# CKMD register map
Vendor: Texas Instruments
Registers are 32-bit, access per field, reset 0x0 unless marked. A register's access mark holds for its fields unless they carry their own. Offsets are as the file gives them; [hi:lo] are bit positions; 'fields as' and 'values as' point back to an identical list.

## CKMD (part 2 of 2) — Clock Controller
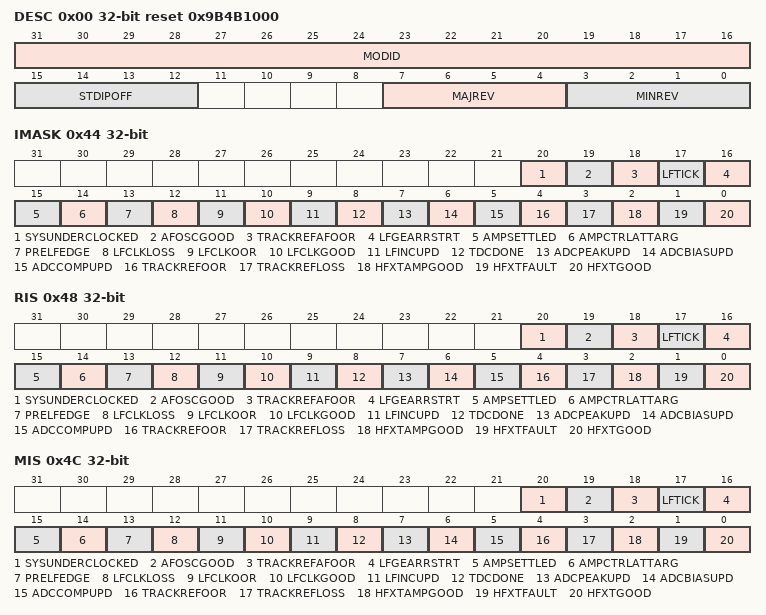
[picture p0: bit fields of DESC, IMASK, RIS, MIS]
0x00 DESC ro reset 0x9B4B1000 — IP Description
  [31:16] MODID — Module identifier
  [15:12] STDIPOFF — Standard IP MMR block offset
  [7:4] MAJREV — Major revision
  [3:0] MINREV — Minor revision
0x44 IMASK — Interrupt mask register
  [20] SYSUNDERCLOCKED rw — Indicates system frequency has been lowered. It will be set only if HFTRACKCTL.UNDERCLK is appropriately configured and HFOSC tracking loop is not running.
  [19] AFOSCGOOD rw — AFOSC good indication.
  [18] TRACKREFAFOOR rw — Out-of-range indication from the AFOSC tracking loop. Indicates that the reference clock frequency of AFOSC tracking loop is out-of-range.
  [17] LFTICK rw — 32kHz TICK to RTC and WDT. Either derived from selected LFCLK or generated from CLKULL in absence of LFCLK.
  [16] LFGEARRSTRT rw — LFINC filter gearing restart. Indicates that the LFINC filter restarted gearing. Subsequent LFINC estimates may have higher variation.
  [15] AMPSETTLED rw — HFXT Amplitude compensation - settled Indicates that the amplitude compensation FSM has reached the SETTLED or TCXOMODE state, and the controls configured in HFXTTARG or HFXTDYN are reached.
  [14] AMPCTRLATTARG rw — HFXT Amplitude compensation - controls at target Indicates that the control values configured in HFXTTARG or HFXTDYN are reached. Applies to Q1CAP, Q2CAP and IREF.
  [13] PRELFEDGE rw — Pre-LF clock edge detect. Indicates that a positive edge occured on the selected pre-LF clock CLKSEL.PRELFCLK' Can be used by software to confirm that a LF clock source is running and within the expected frequency, before selecting it as the main LF clock source.
  [12] LFCLKLOSS rw — LF clock is lost. Indicates that no LF clock edge occured for ~49us (~1.6 times nominal period). The system will automatically fall-back to generating LFTICK based on CLKULL, to avoid timing corruption. Note that this signal is NOT related to the analog LF clock-loss detector which can reset the device during STANDBY.
  [11] LFCLKOOR rw — LF clock period out-of-range. Indicates that a LF clock period was measured to be out-of-range, according to LFQUALCTL.MAXERR.
  [10] LFCLKGOOD rw — LF clock good. Indicates that the LF clock is good, according to the configuration in LFQUALCTL.
  [9] LFINCUPD rw — LFINC updated. Indicates that a new LFINC measurement value is available in CKM.LFCLKSTAT.
  [8] TDCDONE rw — TDC done event. Indicates that the TDC measurement is done.
  [7] ADCPEAKUPD rw — HFXT-ADC PEAK measurement update event. Indicates that the HFXT-ADC PEAK measurement is done.
  [6] ADCBIASUPD rw — HFXT-ADC BIAS measurement update event. Indicates that the HFXT-ADC BIAS measurement is done.
  [5] ADCCOMPUPD rw — HFXT-ADC comparison update event. Indicates that the HFXT-ADC comparison is done.
  [4] TRACKREFOOR rw — Out-of-range indication from the tracking loop. Indicates that the selected reference clock frequency of the tracking loop is out-of-range.
  [3] TRACKREFLOSS rw — Clock loss indication from the tracking loop. Indicates that the selected reference clock of the tracking loop is lost.
  [2] HFXTAMPGOOD rw — HFXT amplitude good indication.
  [1] HFXTFAULT rw — HFXT fault indication. Indicates that HFXT did not start correctly, or its frequency is too low. HFXT will not recover from this fault and has to be restarted. This is only a one-time check at HFXT startup.
  [0] HFXTGOOD rw — HFXT good indication. Indicates that HFXT started correctly. The frequency is not necessarily good enough for radio operation. This is only a one-time check at HFXT startup.
0x48 RIS ro — Raw interrupt flag register
  [20] SYSUNDERCLOCKED — Indicates system frequency has been lowered. It will be set only if HFTRACKCTL.UNDERCLK is appropriately configured and HFOSC tracking loop is not running.
  [19] AFOSCGOOD — AFOSC good indication.
  [18] TRACKREFAFOOR — Out-of-range indication from the AFOSC tracking loop. Indicates that the reference clock frequency of AFOSC tracking loop is out-of-range.
  [17] LFTICK — 32kHz TICK to RTC and WDT. Either derived from selected LFCLK or generated from CLKULL in absence of LFCLK.
  [16] LFGEARRSTRT — LFINC filter gearing restart. Indicates that the LFINC filter restarted gearing. Subsequent LFINC estimates may have higher variation.
  [15] AMPSETTLED — HFXT Amplitude compensation - settled Indicates that the amplitude compensation FSM has reached the SETTLED or TCXOMODE state, and the controls configured in HFXTTARG or HFXTDYN are reached.
  [14] AMPCTRLATTARG — HFXT Amplitude compensation - controls at target Indicates that the control values configured in HFXTTARG or HFXTDYN are reached. Applies to Q1CAP, Q2CAP and IREF.
  [13] PRELFEDGE — Pre-LF clock edge detect. Indicates that a positive edge occured on the selected pre-LF clock CLKSEL.PRELFCLK' Can be used by software to confirm that a LF clock source is running and within the expected frequency, before selecting it as the main LF clock source.
  [12] LFCLKLOSS — LF clock is lost. Indicates that no LF clock edge occured for ~49us (~1.6 times nominal period). The system will automatically fall-back to generating LFTICK based on CLKULL, to avoid timing corruption. Note that this signal is NOT related to the analog LF clock-loss detector which can reset the device during STANDBY.
  [11] LFCLKOOR — LF clock period out-of-range. Indicates that a LF clock period was measured to be out-of-range, according to LFQUALCTL.MAXERR.
  [10] LFCLKGOOD — LF clock good. Indicates that the LF clock is good, according to the configuration in LFQUALCTL.
  [9] LFINCUPD — LFINC updated. Indicates that a new LFINC measurement value is available in CKM.LFCLKSTAT.
  [8] TDCDONE — TDC done event. Indicates that the TDC measurement is done.
  [7] ADCPEAKUPD — HFXT-ADC PEAK measurement update event. Indicates that the HFXT-ADC PEAK measurement is done.
  [6] ADCBIASUPD — HFXT-ADC BIAS measurement update event. Indicates that the HFXT-ADC BIAS measurement is done.
  [5] ADCCOMPUPD — HFXT-ADC comparison update event. Indicates that the HFXT-ADC comparison is done.
  [4] TRACKREFOOR — Out-of-range indication from the tracking loop. Indicates that the selected reference clock frequency of the tracking loop is out-of-range.
  [3] TRACKREFLOSS — Clock loss indication from the tracking loop. Indicates that the selected reference clock of the tracking loop is lost.
  [2] HFXTAMPGOOD — HFXT amplitude good indication.
  [1] HFXTFAULT — HFXT fault indication. Indicates that HFXT did not start correctly, or its frequency is too low. HFXT will not recover from this fault and has to be restarted. This is only a one-time check at HFXT startup.
  [0] HFXTGOOD — HFXT good indication. Indicates that HFXT started correctly. The frequency is not necessarily good enough for radio operation. This is only a one-time check at HFXT startup.
0x4C MIS ro — Masked interrupt flag register
  fields as RIS
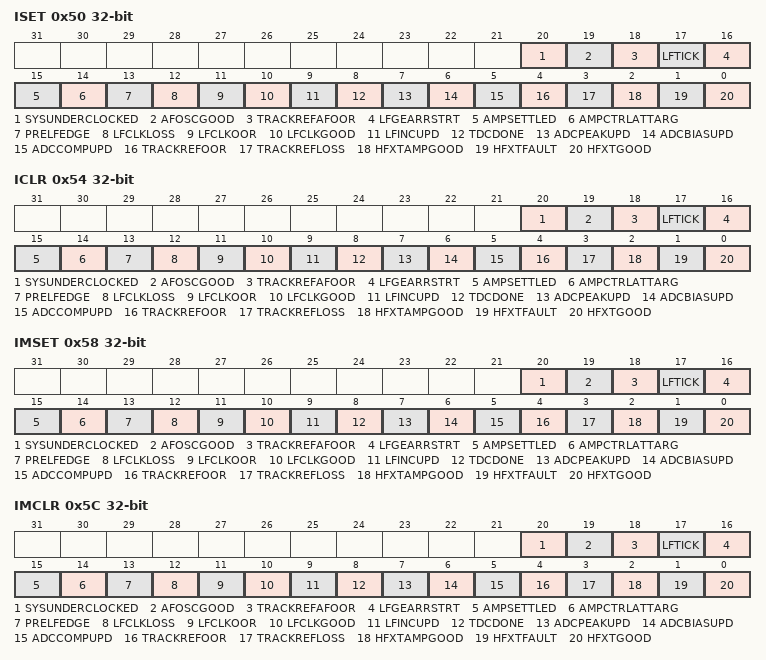
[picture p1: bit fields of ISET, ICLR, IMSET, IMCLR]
0x50 ISET — Interrupt flag set register
  [20] SYSUNDERCLOCKED wo — Indicates system frequency has been lowered. It will be set only if HFTRACKCTL.UNDERCLK is appropriately configured and HFOSC tracking loop is not running.
  [19] AFOSCGOOD wo — AFOSC good indication.
  [18] TRACKREFAFOOR wo — Out-of-range indication from the AFOSC tracking loop. Indicates that the reference clock frequency of AFOSC tracking loop is out-of-range.
  [17] LFTICK wo — 32kHz TICK to RTC and WDT. Either derived from selected LFCLK or generated from CLKULL in absence of LFCLK.
  [16] LFGEARRSTRT wo — LFINC filter gearing restart. Indicates that the LFINC filter restarted gearing. Subsequent LFINC estimates may have higher variation.
  [15] AMPSETTLED wo — HFXT Amplitude compensation - settled Indicates that the amplitude compensation FSM has reached the SETTLED or TCXOMODE state, and the controls configured in HFXTTARG or HFXTDYN are reached.
  [14] AMPCTRLATTARG wo — HFXT Amplitude compensation - controls at target Indicates that the control values configured in HFXTTARG or HFXTDYN are reached. Applies to Q1CAP, Q2CAP and IREF.
  [13] PRELFEDGE wo — Pre-LF clock edge detect. Indicates that a positive edge occured on the selected pre-LF clock CLKSEL.PRELFCLK' Can be used by software to confirm that a LF clock source is running and within the expected frequency, before selecting it as the main LF clock source.
  [12] LFCLKLOSS wo — LF clock is lost. Indicates that no LF clock edge occured for ~49us (~1.6 times nominal period). The system will automatically fall-back to generating LFTICK based on CLKULL, to avoid timing corruption. Note that this signal is NOT related to the analog LF clock-loss detector which can reset the device during STANDBY.
  [11] LFCLKOOR wo — LF clock period out-of-range. Indicates that a LF clock period was measured to be out-of-range, according to LFQUALCTL.MAXERR.
  [10] LFCLKGOOD wo — LF clock good. Indicates that the LF clock is good, according to the configuration in LFQUALCTL.
  [9] LFINCUPD wo — LFINC updated. Indicates that a new LFINC measurement value is available in CKM.LFCLKSTAT.
  [8] TDCDONE wo — TDC done event. Indicates that the TDC measurement is done.
  [7] ADCPEAKUPD wo — HFXT-ADC PEAK measurement update event. Indicates that the HFXT-ADC PEAK measurement is done.
  [6] ADCBIASUPD wo — HFXT-ADC BIAS measurement update event. Indicates that the HFXT-ADC BIAS measurement is done.
  [5] ADCCOMPUPD wo — HFXT-ADC comparison update event. Indicates that the HFXT-ADC comparison is done.
  [4] TRACKREFOOR wo — Out-of-range indication from the tracking loop. Indicates that the selected reference clock frequency of the tracking loop is out-of-range.
  [3] TRACKREFLOSS wo — Clock loss indication from the tracking loop. Indicates that the selected reference clock of the tracking loop is lost.
  [2] HFXTAMPGOOD wo — HFXT amplitude good indication.
  [1] HFXTFAULT wo — HFXT fault indication. Indicates that HFXT did not start correctly, or its frequency is too low. HFXT will not recover from this fault and has to be restarted. This is only a one-time check at HFXT startup.
  [0] HFXTGOOD wo — HFXT good indication. Indicates that HFXT started correctly. The frequency is not necessarily good enough for radio operation. This is only a one-time check at HFXT startup.
0x54 ICLR — Interrupt flag clear register
  fields as ISET
0x58 IMSET — Interrupt mask set register
  fields as ISET
0x5C IMCLR — Interrupt mask clear register
  fields as ISET
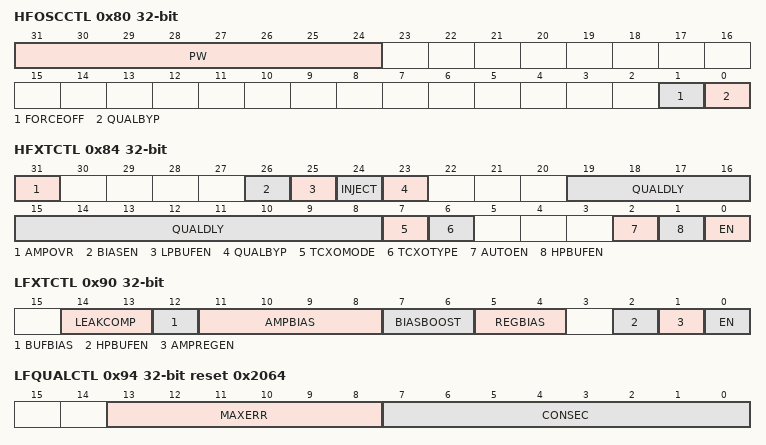
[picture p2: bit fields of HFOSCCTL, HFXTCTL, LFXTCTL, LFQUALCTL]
0x80 HFOSCCTL — High frequency oscillator control
  [31:24] PW wo — Password protection for QUALBYP and FORCEOFF. Write this field to 0xA5 to accept writes to QUALBYP and FORCEOFF.
  [1] FORCEOFF rw — Force HFOSC off. Once this MMR is set, the system will stop. The only way to start the system again is system reset. This field is locked using the global-lock within SYS0.
  [0] QUALBYP rw — Clock qualification bypass. HFOSC qualification will skip a fixed number of clock cycles to prevent glitches or frequency overshoots from reaching the system. Setting this bit will bypass the qualification. This bit can be locked in SYS0. If unlocked, it is password protected with PW.
0x84 HFXTCTL — High frequency crystal control
  [31] AMPOVR rw — Software override for the amplitude compensation FSM Directly use control values in CKM.HFXTDYN0 and CKM.HFXTDYN1. Control injection and clock buffer using INJECT and LPBUFEN.
  [26] BIASEN rw — HFXT bias enable. Controls the biasing if AMPOVR is set. Otherwise, the biasing is controlled by the amplitude compensation FSM.
  [25] LPBUFEN rw — Low power clock buffer enable. Controls the clock buffer if AMPOVR is set. Otherwise, the buffer is controlled by the amplitude compensation FSM.
  [24] INJECT rw — Control HFXT injection if AMPOVR is set.
  [23] QUALBYP rw — Bypass HFXT clock qualification. Enables HFXT propagation to the system without waiting for the qualification circuit.
  [19:8] QUALDLY rw — Skip potentially unstable clock cycles after enabling HFXT. Number of cycles skipped is 8*QUALDLY.
  [7] TCXOMODE rw — Temperature compensated crystal oscillator mode. Set this bit if a TXCO is connected.
  [6] TCXOTYPE rw — Type of temperature compensated crystal used. Only has effect if TCXOMODE is set.
    1=CMOS; 0=CLIPPEDSINE
  [2] AUTOEN rw — Automatic enable. If this bit is set, EN will automatically be set at wakeup or before (using pre-wake mechanism in RTC).
  [1] HPBUFEN rw — High performance clock buffer enable. This bit controls the clock output for the RF PLL. It is required for radio operation.
  [0] EN rw — HFXT enable. Setting this bit will enable HFXT. It will automatically be cleared upon STANDBY entry. If AUTOEN is set, this bit will be set automatically on wakeup or before (pre-wake mechanism in RTC).
0x8C LFOSCCTL — Low frequency oscillator control
  [0] EN rw — LFOSC enable
0x90 LFXTCTL — Low frequency crystal control
  [14:13] LEAKCOMP rw — Leakage compensation control
    3=OFF (No leakage compensation); 1=HALF (Half leakage compensation); 0=FULL (Full leakage compensation)
  [12] BUFBIAS rw — Control the BIAS current of the input amp in LP buffer
    1=MAX (Maximum bias current: 50nA); 0=MIN (Minimum bias current: 25nA)
  [11:8] AMPBIAS rw — Adjust current mirror ratio into oscillator core. This value is depending on crystal and is set by FW. This field uses a 2's complement encoding.
  [7:6] BIASBOOST rw — Boost oscillator amplitude This value depends on the crystal and needs to be configured by Firmware.
  [5:4] REGBIAS rw — Regulation loop bias resistor value This value depends on the crystal and needs to be configured by Firmware.
  [2] HPBUFEN rw — Control the buffer used. In normal operation, low-power buffer is used in all device modes. The high-performance buffer is only used for test purposes.
  [1] AMPREGEN rw — Amplitude regulation loop enable
  [0] EN rw — LFXT enable
0x94 LFQUALCTL reset 0x2064 — Low frequency clock qualification control
  [13:8] MAXERR rw — Maximum LFCLK period error. Value given in microseconds, 3 integer bits + 3 fractional bits.
  [7:0] CONSEC rw — Number of consecutive times the LFCLK period error has to be smaller than MAXERR to be considered "good". Setting this value to 0 will bypass clock qualification, and the "good" indicator will always be 1.
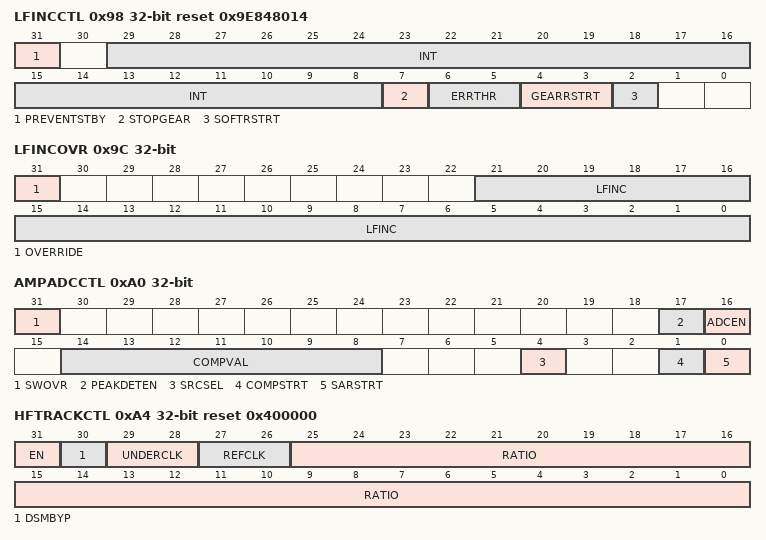
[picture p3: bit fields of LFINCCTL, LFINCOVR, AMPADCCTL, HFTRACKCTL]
0x98 LFINCCTL reset 0x9E848014 — Low frequency time increment control
  [31] PREVENTSTBY rw — Controls if the LFINC filter prevents STANBY entry until settled.
    1=ON (Enable. Prevent STANDBY entry.); 0=OFF (Disable. Do not prevent STANDBY entry.)
  [29:8] INT rw — Integral part of the LFINC filter. This value is updated by Hardware to reflect the current state of the filter. It can also be written to change the current state.
  [7] STOPGEAR rw — Controls the final gear of the LFINC filter.
    1=HIGH (Highest final gear. Best dynamic frequency tracking, but higher variation in filter value.); 0=LOW (Lowest final gear. Best settling, but less dynamic frequency tracking.)
  [6:5] ERRTHR rw — Controls the threshold for gearing restart of the LFINC filter. Only effective if GEARRSTRT is not ONETHR or TWOTHR.
    3=SMALL (Restart gearing on small error. Potentially more false restarts, faster response on small frequency shifts.); 2=MIDSMALL (Middle value towards SMALL.); 1=MIDLARGE (Middle value towards LARGE.); 0=LARGE (Restart gearing on large error. Fewer false restarts, slower response on small frequency shifts.)
  [4:3] GEARRSTRT rw — Controls gearing restart of the LFINC filter.
    2=TWOTHR (Restart gearing when the error accumulator crosses the threshold twice in a row.); 1=ONETHR (Restart gearing when the error accumulator crosses the threshold once.); 0=NEVER (Never restart gearing. Very stable filter value, but very slow response on frequency changes.)
  [2] SOFTRSTRT rw — Use a higher gear after re-enabling / wakeup. The filter will require 16-24 LFCLK periods to settle (depending on STOPGEAR), but may respond faster to frequency changes during STANDBY.
    1=ON (Use soft gearing restarts); 0=OFF (Don't use soft gearing restarts)
0x9C LFINCOVR — Low frequency time increment override control
  [31] OVERRIDE rw — Override LF increment Use the value provided in LFINC instead of the value calculated by Hardware.
  [21:0] LFINC rw — LF increment value This value is used when OVERRIDE is set to 1. Otherwise the value is calculated automatically. The current LFINC value can be read from [CKM.LFCLKSTAT.LFINC].
0xA0 AMPADCCTL — Amplitude ADC control
  [31] SWOVR rw — Software override. Control Amplitude ADC from software
  [17] PEAKDETEN rw — Enable HFXT Peak Detector. If the peak detector is used by the AMPCOMP FSM, this bit can be used to keep the peak detector always enabled. If SWOVR is set, this bit directly controls the peak detector.
    1=ENABLE (Enable peak detector); 0=DISABLE (Disable peak detector (unless requested by AMPCOMP FSM))
  [16] ADCEN rw — Enable Amplitude ADC. If the ADC is used by the AMPCOMP FSM, this bit can be used to keep the ADC always enabled. If SWOVR is set, this bit directly controls the ADC.
    1=ENABLE (Enable ADC); 0=DISABLE (Disable ADC (unless requested by AMPCOMP FSM))
  [14:8] COMPVAL rw — Comparator reference input in compare mode This bitfield is only active if SWOVR is set. SRCSEL selects the source to be compared. Result will be available in CKM.AMPADCSTAT.
  [4] SRCSEL rw — Select the input to the ADC Only active if SWOVR is set.
    1=PEAK (Measure HFXT peak voltage); 0=BIAS (Measure bias voltage)
  [1] COMPSTRT rw — Start a comparison This bit is only active if SWOVR is set. SRCSEL selects the source to be measured. COMPVAL configures the threshold value. Result will be available in CKM.AMPADCSTAT.
  [0] SARSTRT rw — Start a SAR conversion This bit is only active if SWOVR is set. SRCSEL selects the source to be measured. Result will be available in CKM.AMPADCSTAT.
0xA4 HFTRACKCTL rw reset 0x400000 — High frequency tracking loop control
  [31] EN — Enable tracking loop.
  [30] DSMBYP — Bypass Delta-Sigma-Modulation of fine trim.
  [29:28] UNDERCLK — When the HFOSC tracking loop is not running, this bitfield can be used to set the condition to automatically lower the HFOSC frequency. This will prevent frequency drift that may lead to SOC instability.
    3=BOTH (Temperature event from Batmon or Timer event); 2=BATMON (Temperature event from Batmon); 1=TIMER (Timer event); 0=DIS (Disable)
  [27:26] REFCLK — Select the reference clock for the tracking loop. Change only while the tracking loop is disabled.
    2=GPI (Select GPI as reference clock.); 1=LRF (Select LRF reference clock.); 0=HFXT (Select HFXT as reference clock.)
  [25:0] RATIO — Ratio. Ratio format is 2b.24b
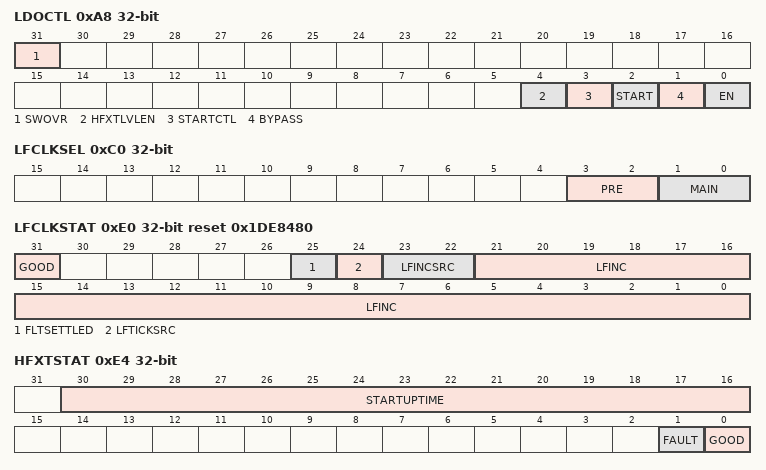
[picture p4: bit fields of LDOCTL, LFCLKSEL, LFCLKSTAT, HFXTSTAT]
0xA8 LDOCTL — LDO control By default, the LDO is controlled by the HFXT Amplitude compensation. This register is used for software overrides.
  [31] SWOVR rw — Software override. Control LDO from software
  [4] HFXTLVLEN rw — Enable levelshifters from ULL to VCKM. Needs to be timer-based. Worst-case LDO startup time is 5us across PVT.
  [3] STARTCTL rw — Enable faster startup. This bit should be set together with EN, and cleared after 5us.
  [2] START rw — Enable faster startup. This bit should be set together with EN, and cleared after 5us.
  [1] BYPASS rw — Bypass LDO
  [0] EN rw — Enable LDO
0xAC NABIASCTL — Nanoamp-bias control
  [0] EN rw — Enable nanoamp-bias
0xB0 LFMONCTL — Low-frequency clock-monitor control
  [0] EN rw — Enable LFMONITOR. Enable only after a LF clock source has been selected, enabled and is stable. If LFMONITOR detects a clock loss, the system will be reset.
0xC0 LFCLKSEL — Low frequency clock selection
  [3:2] PRE rw — Select low frequency clock source for the PRELFCLK interrupt. Can be used by Software to confirm that the clock is running and it's frequency is good, before selecting it in MAIN.
    3=EXTLF (External LF clock through GPI.); 2=LFXT (Low frequency crystal oscillator); 1=LFOSC (Low frequency on-chip oscillator); 0=NONE (No clock. Output will be tied low.)
  [1:0] MAIN rw — Select the main low frequency clock source. If running, this clock will be used to generate LFTICK and as CLKULL during STANDBY. If not running, LFTICK will be generated from HFOSC and STANDBY entry will be prevented.
    3=EXTLF (External LF clock through GPI.); 2=LFXT (Low frequency crystal oscillator); 1=LFOSC (Low frequency on-chip oscillator); 0=FAKE (No LF clock selected. LFTICK will be generated from HFOSC, STANDBY entry will be prevented.)
0xC4 TDCCLKSEL — TDC clock selection
  [2:0] REFCLK rw — Select reference clock for the TDC.
    5=HFXT (48MHz HFXT); 4=AFOSC (AFOSC clock div by 2); 3=GPI (General purpose input signal); 2=CLKULL (24MHz CLKULL); 1=CLKSVT (96MHz HFOSC clock div by 2); 0=NONE (No reference clock)
0xC8 ADCCLKSEL — ADC clock selection
  [1:0] SRC rw — Select ADC clock source Change only while ADC is disabled!
    1=HFXT (48MHz HFXT); 0=CLKSVT (48MHz CLKSVT)
0xE0 LFCLKSTAT ro reset 0x1DE8480 — Low-frequency clock status
  [31] GOOD — Low frequency clock good Note: This is only a coarse frequency check based on LFQUALCTL. The clock may not be accurate enough for timing purposes.
  [25] FLTSETTLED — LFINC filter is running and settled.
  [24] LFTICKSRC — Source of LFTICK.
    1=FAKE (LFTICK generated from CLKULL (LFCLK not available)); 0=LFCLK (LFTICK generated from the selected LFCLK)
  [23:22] LFINCSRC — Source of LFINC used by the RTC. This value depends on LFINCOVR.OVERRIDE, LFINCCTL.AVG, LFINCCTL.EN and the device state (ACTIVE/STANDBY).
    3=FAKE (Using FAKE LFTICKs with corresponding LFINC value.); 2=OVERRIDE (Using override value from LFINCOVR.LFINC); 1=AVG (Using filtered / average value. This value is updated by hardware and can be read and updated in LFINCCTL.INT.); 0=MEAS (Using measured value. This value is updated by hardware and can be read from LFINC.)
  [21:0] LFINC — Measured value of LFINC. Given in microseconds with 16 fractional bits. This value is calculated by Hardware. It is the LFCLK period according to CLKULL cycles.
0xE4 HFXTSTAT ro — HFXT status information
  [30:16] STARTUPTIME — HFXT startup time Can be used by software to plan starting HFXT ahead in time. Measured whenever HFXT is enabled in CLKULL periods (24MHz), from [CKM.HFXTCTL.EN] until the clock is good for radio operation (amplitude compensation is settled).
  [1] FAULT — HFXT clock fault Indicates a lower than expected HFXT frequency. HFXT will not recover from this fault, disabling and re-enabling HFXT is required.
  [0] GOOD — HFXT clock available
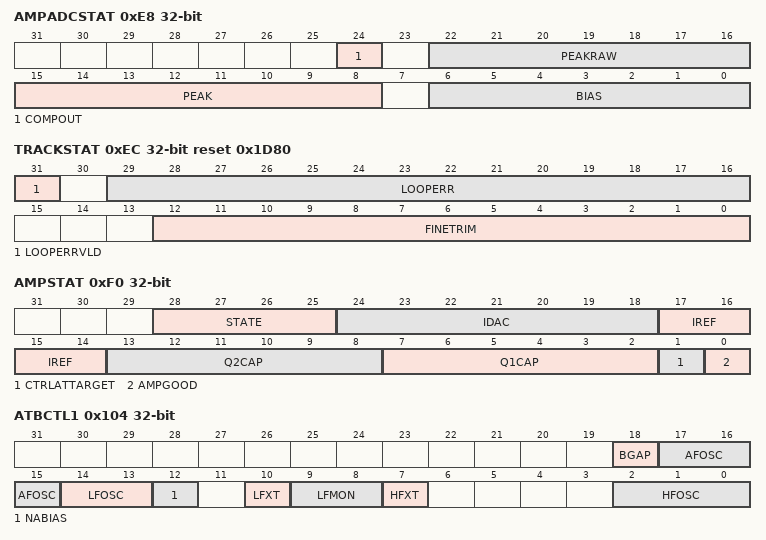
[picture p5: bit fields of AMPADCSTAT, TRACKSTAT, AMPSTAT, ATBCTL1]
0xE8 AMPADCSTAT ro — HFXT Amplitude ADC Status
  [24] COMPOUT — Most recent comparison output
  [22:16] PEAKRAW — Most recently measured peak voltage - raw This value is the raw output of the HFXT ADC. For the actual peak voltage use the value (PEAK + 0.0150)/0.74 + K, where 'K' is a function of process variation and is stored in FCFG1 register.
  [15:8] PEAK — Most recently measured peak voltage - bias corrected This value is computed as 2*PEAKRAW-BIAS Actual voltage = (2*PEAKRAW-BIAS - 0.015)/0.74 + K, where 'K' is a function of process variation and is stored in FCFG1 register.
  [6:0] BIAS — Most recently measured bias voltage
0xEC TRACKSTAT ro reset 0x1D80 — HF tracking loop status information
  [31] LOOPERRVLD — Current HFOSC tracking error valid This bit is one if the tracking loop is running and the error value is valid.
  [29:16] LOOPERR — Current HFOSC tracking error This field uses the internal fractional representation (sign, 9 integer bits, 4 fractional bits).
  [12:0] FINETRIM — Current HFOSC Fine-trim value This field uses the internal fractional representation (sign, 5 integer bits, 7 fractional bits). The actual trim value applied to the oscillator is delta-sigma modulated 6 bits non-signed (inverted sign bit + integer bits). INTERNAL This field can be written by also writing a magic value (0xA5) into LOOPERR (bits 23:16)
0xF0 AMPSTAT ro — HFXT Amplitude Compensation Status
  [28:25] STATE — Current AMPCOMP FSM state.
    15=SETTLED; 14=UPDATEUP; 12=TXCOMODE; 10=SHUTDN0; 7=INJWAIT; 6=UPDATEDN; 5=RAMP0; 4=RAMP1; 3=INJECT; 2=SHUTDN1; 1=LDOSTART; 0=IDLE
  [24:18] IDAC — Current IDAC control value.
  [17:14] IREF — Current IREF control value.
  [13:8] Q2CAP — Current Q2CAP control value.
  [7:2] Q1CAP — Current Q1CAP control value.
  [1] CTRLATTARGET — HFXT control values match target values. This applies to IREF, Q1CAP, Q2CAP values.
  [0] AMPGOOD — HFXT amplitude good
0x100 ATBCTL0 — Analog test bus controls All fields within this register are locked using the global-lock within SYS0.
  [23:0] SEL rw — Testmux selection ALWAYS write this signal to 0 (OFF), before selecting another configuration! Not following this might result in device damage.
    0x90000=AFOSCTESTCLK (ull_ckm_afosc_testclk connected to vr_atb_ckmanatop_clk); 0x70000=LFXTTESTCLK (ull_ckm_lfxt_testclk connected to vr_atb_ckmanatop_clk); 0x50000=LFOSCTESTCLK (ull_ckm_lfosc_testclk connected to vr_atb_ckmanatop_clk); 0x30000=HFXTTESTCLK (ull_ckm_hfxt_testclk connected to vr_atb_ckmanatop_clk); 0x10000=HFOSCTESTCLK (ull_ckm_hfosc_testclk connected to vr_atb_ckmanatop_clk); 0x4000=AFOSCOUT (vr_atb_afosc connected to vr_atb_ckmanatop_ana); 0x1000=LFMONVTEST (vr_atb_lfmonitor_vtest connected to vr_atb_ckmanatop_ana); 0x100=HFOSCOUT (vr_atb_hfosc_out connected to vr_atb_ckmanatop_ana); 128=NABIASITEST (vr_atb_nabias_itest_250n_dn connected to vr_atb_ckmanatop_ana); 64=ADCDACOUT (vr_atb_hfxtadc_dacout connected to vr_atb_ckmanatop_ana); 32=ADCCOMPIN (vr_atb_hfxtadc_compin connected to vr_atb_ckmanatop_ana); 16=ADCCOMPOUT (vr_atb_hfxtadc_compout connected to vr_atb_ckmanatop_ana); 8=LFXTANA (vr_atb_lfxt_ana connected to vr_atb_ckmanatop_ana); 2=VDDCKM (vr_atb_ckmldo_vddckm connected to vr_atb_ckmanatop_ana); 1=HFXTANA (vr_atb_hfxt_ana connected to vr_atb_ckmanatop_ana); 0=OFF (No signal connected to ATB. All outputs high impedant)
0x104 ATBCTL1 — Analog test bus controls All fields within this register are locked using the global-lock within SYS0.
  [18] BGAP rw — Control bandgap test output signals
  [17:15] AFOSC rw — Control AFOSC test output signals
  [14:13] LFOSC rw — Control LFOSC test output signals
    3=BOTH (Both LFOSC test signals (TESTCLK, VDD LOCAL)); 2=VDDLOCAL (LFOSC VDD LOCAL); 1=TESTCLK (LFOSC test clock); 0=OFF (No output signal selected)
  [12] NABIAS rw — Enable NABIAS test mode.
  [10] LFXT rw — Control LFXT test output signals
    1=TESTCLK (LFXT test clock); 0=OFF (No output signal selected)
  [9:8] LFMON rw — Control LFMON test output signals
    2=TEST2 (Test signal 2 / in phase with inverted clock signal); 1=TEST1 (Test signal 1 / in phase with LF clock); 0=OFF (No output signal selected)
  [7] HFXT rw — Enable HFXT test mode.
  [2:0] HFOSC rw — Control HFOSC test output signals
